# NUC029DE_v1 register map
File version: 1.0
Registers are 32-bit, read-write, reset 0x0 unless marked. A register's access mark holds for its fields unless they carry their own. Offsets are from the block's base; [hi:lo] are bit positions; {n}, {i} and the like mark numbered series; 'fields as' and 'values as' point back to an identical list.

## I2C0 — I2C Register Map
Base 0x40020000
Same registers: I2C1 0x40120000
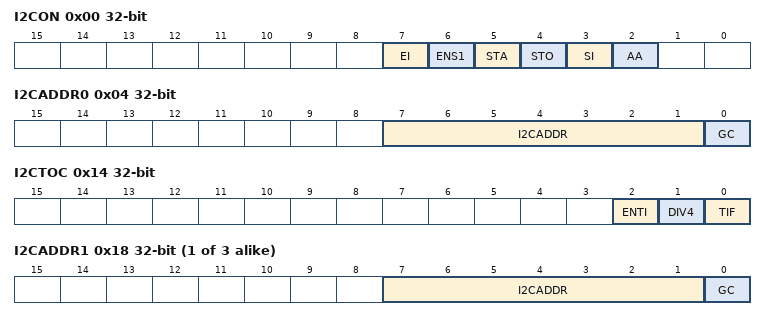
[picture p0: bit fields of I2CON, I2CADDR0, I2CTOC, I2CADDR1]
0x00 I2CON — I2C Control Register
  [7] EI — Interrupt Enable Coontrol
    0=I2C interrupt Disabled; 1=I2C interrupt Enabled
  [6] ENS1 — I2C Controller Enable Coontrol
    0=Disabled; 1=Enabled
  [5] STA — I2C START Control. Setting STA to logic 1 to enter Master mode, the I2C hardware sends a START or repeat START condition to bus when the bus is free.
  [4] STO — I2C STOP Control. In Master mode, setting STO to transmit a STOP condition to bus then I2C hardware will check the bus condition if a STOP condition is detected this bit will be cleared by hardware automatically. In a slave mode, setting STO resets I2C hardware to the defined "not addressed" slave mode. This means it is NO LONGER in the slave receiver mode to receive data from the master transmit device.
  [3] SI — I2C Interrupt Flag. When a new I2C state is present in the I2CSTATUS register, the SI flag is set by hardware, and if bit EI (I2CON [7]) is set, the I2C interrupt is requested. SI must be cleared by software. Clear SI by writing 1 to this bit.
  [2] AA — Assert Acknowledge Control
0x04 I2CADDR0 — I2C Slave Address Register0
  [7:1] I2CADDR — I2C Address Register. The content of this register is irrelevant when I2C is in Master mode. In the slave mode, the seven most significant bits must be loaded with the chip's own address. The I2C hardware will react if either of the address is matched.
  [0] GC — General Call Function
    0=General Call Function Disabled; 1=General Call Function Enabled
0x08 I2CDAT — I2C Data Register
  [7:0] I2CDAT — I2C Data Register. This field is located with the 8-bit transferred data of I2C serial port.
0x0C I2CSTATUS ro reset 0xF8
  [7:0] I2CSTATUS — I2C Status Register. There are 26 possible status codes. When I2CSTATUS contains 0xF8, no serial interrupt is requested. In addition, states 0x00 stands for a Bus Error. A Bus Error occurs when a START or STOP condition is present at an illegal position in the formation frame. Example of illegal position are during the serial transfer of an address byte, a data byte or an acknowledge bit.
0x10 I2CLK — I2C Clock Divided Register
  [7:0] I2CLK — I2C Clock Divided Register. Note: The minimum value of I2CLK is 4.
0x14 I2CTOC — I2C Time-out Counter Register
  [2] ENTI — Time-Out Counter Enable Coontrol. When Enabled, the 14-bit time-out counter will start counting when SI (I2CON[3]) is clear. Setting flag SI SI(I2CON[3]) to high will reset counter and re-start up counting after SI SI(I2CON[3]) is cleared.
    0=Disabled; 1=Enabled
  [1] DIV4 — Time-Out Counter Input Clock Divided By 4. When Enabled, The time-out period is extend 4 times.
    0=Disabled; 1=Enabled
  [0] TIF — Time-Out Flag. This bit is set by hardware when I2C time-out happened and it can interrupt CPU if I2C interrupt enable bit EI (I2CON[7]) is set to 1. Note: Write 1 to clear this bit.
{0x14+4i} I2CADDR{i} (i=1..3) — I2C Slave Address Register{i}
  fields as I2CADDR0
{0x24+4i} I2CADM{i} (i=0..3) — I2C Slave Address Mask Register{i}
  [7:1] I2CADM — I2C Address Mask Register. I2C bus controllers support multiple address recognition with four address mask register. When the bit in the address mask register is set to one, it means the received corresponding address bit is don't-care. If the bit is set to zero, that means the received corresponding register bit should be exact the same as address register.
    0=Mask Disabled (the received corresponding register bit should be exact the same as address register.); 1=Mask Enabled (the received corresponding address bit is don't care.)
0x3C I2CWKUPCON — I2C Wake-up Control Register
  [0] WKUPEN — I2C Wake-Up Enable Coontrol
    0=I2C wake-up function Disabled; 1=I2C wake-up function Enabled
0x40 I2CWKUPSTS — I2C Wake-up Status Register
  [0] WKUPIF — I2C Wake-Up Flag. Note: Software can write 1 to clear this bit.
    0=Chip is not woken-up from Power-down mode by I2C; 1=Chip is woken-up from Power-down mode by I2C
